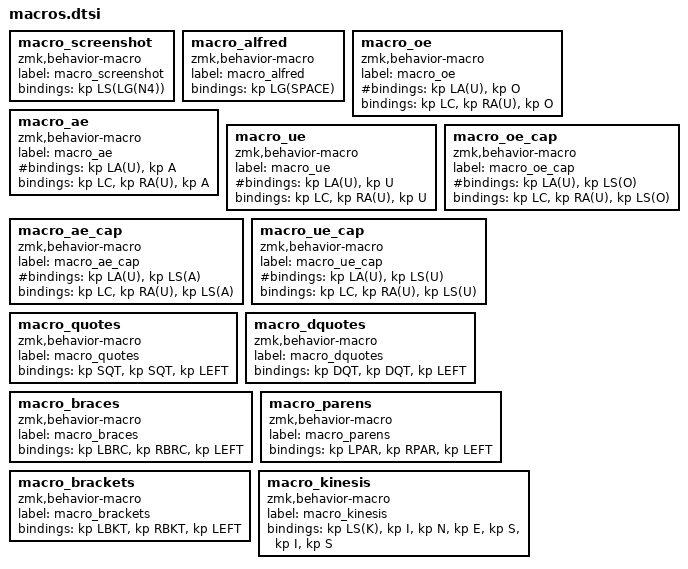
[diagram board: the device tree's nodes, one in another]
macro_screenshot: macro_screenshot{
compatible = "zmk,behavior-macro";
label = "macro_screenshot";
#binding-cells = <0>;
bindings = <&kp LS(LG(N4))>;
};
macro_alfred: macro_alfred{
compatible = "zmk,behavior-macro";
label = "macro_alfred";
#binding-cells = <0>;
bindings = <&kp LG(SPACE)>;
};
macro_oe: macro_oe{
compatible = "zmk,behavior-macro";
label = "macro_oe";
#binding-cells = <0>;
#MacOS
#bindings = <&kp LA(U)>, <&kp O>;
#Windows
bindings = <&kp LC>, <&kp RA(U)>, <&kp O>;
};
macro_ae: macro_ae{
compatible = "zmk,behavior-macro";
label = "macro_ae";
#binding-cells = <0>;
#MacOS
#bindings = <&kp LA(U)>, <&kp A>;
#Windows
bindings = <&kp LC>, <&kp RA(U)>, <&kp A>;
};
macro_ue: macro_ue{
compatible = "zmk,behavior-macro";
label = "macro_ue";
#binding-cells = <0>;
#MacOS
#bindings = <&kp LA(U)>, <&kp U>;
#Windows
bindings = <&kp LC>, <&kp RA(U)>, <&kp U>;
};
macro_oe_cap: macro_oe_cap{
compatible = "zmk,behavior-macro";
label = "macro_oe_cap";
#binding-cells = <0>;
#MacOS
#bindings = <&kp LA(U)>, <&kp LS(O)>;
#Windows
bindings = <&kp LC>, <&kp RA(U)>, <&kp LS(O)>;
};
macro_ae_cap: macro_ae_cap{
compatible = "zmk,behavior-macro";
label = "macro_ae_cap";
#binding-cells = <0>;
#MacOS
#bindings = <&kp LA(U)>, <&kp LS(A)>;
#Windows
bindings = <&kp LC>, <&kp RA(U)>, <&kp LS(A)>;
};
macro_ue_cap: macro_ue_cap{
compatible = "zmk,behavior-macro";
label = "macro_ue_cap";
#binding-cells = <0>;
#MacOS
#bindings = <&kp LA(U)>, <&kp LS(U)>;
#Windows
bindings = <&kp LC>, <&kp RA(U)>, <&kp LS(U)>;
};
macro_quotes: macro_quotes{
compatible = "zmk,behavior-macro";
label = "macro_quotes";
#binding-cells = <0>;
bindings = <&kp SQT>, <&kp SQT>, <&kp LEFT>;
};
macro_dquotes: macro_dquotes{
compatible = "zmk,behavior-macro";
label = "macro_dquotes";
#binding-cells = <0>;
bindings = <&kp DQT>, <&kp DQT>, <&kp LEFT>;
};
macro_braces: macro_braces{
compatible = "zmk,behavior-macro";
label = "macro_braces";
#binding-cells = <0>;
bindings = <&kp LBRC>, <&kp RBRC>, <&kp LEFT>;
};
macro_parens: macro_parens{
compatible = "zmk,behavior-macro";
label = "macro_parens";
#binding-cells = <0>;
bindings = <&kp LPAR>, <&kp RPAR>, <&kp LEFT>;
};
macro_brackets: macro_brackets{
compatible = "zmk,behavior-macro";
label = "macro_brackets";
#binding-cells = <0>;
bindings = <&kp LBKT>, <&kp RBKT>, <&kp LEFT>;
};
macro_kinesis: macro_kinesis{
compatible = "zmk,behavior-macro";
label = "macro_kinesis";
#binding-cells = <0>;
bindings = <&kp LS(K)>, <&kp I>, <&kp N>, <&kp E>, <&kp S>, <&kp I>, <&kp S>;
};

